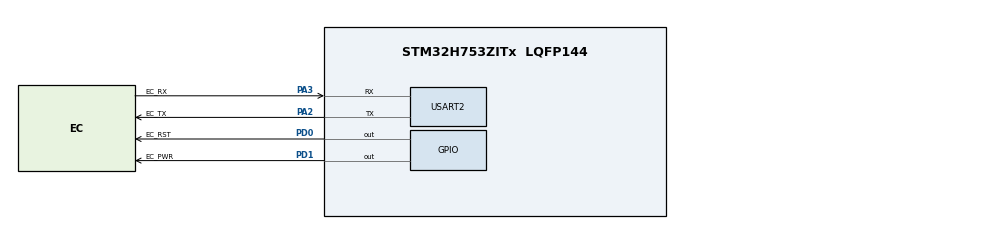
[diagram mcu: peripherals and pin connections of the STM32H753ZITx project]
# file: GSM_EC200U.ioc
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CORTEX_M7.default_mode_Activation=1
Mcu.Family=STM32H7
Mcu.Name=STM32H753ZITx
Mcu.Package=LQFP144
NVIC.PriorityGroup=NVIC_PRIORITYGROUP_4
NVIC.TIM8_TRG_COM_TIM14_IRQn=true\:0\:0\:false\:false\:true\:true\:true\:true
NVIC.USART2_IRQn=true\:0\:0\:false\:false\:true\:true\:true\:true
PA2.GPIO_Label=EC_TX
PA2.Mode=Asynchronous
PA2.Signal=USART2_TX
PA3.GPIO_Label=EC_RX
PA3.Mode=Asynchronous
PA3.Signal=USART2_RX
PD0.GPIO_Label=EC_RST
PD0.GPIO_PuPd=GPIO_PULLDOWN
PD0.Signal=GPIO_Output
PD1.GPIO_Label=EC_PWR
PD1.GPIO_PuPd=GPIO_PULLDOWN
PD1.Signal=GPIO_Output
ProjectManager.HeapSize=0x200
ProjectManager.StackSize=0x400
ProjectManager.TargetToolchain=STM32CubeIDE
RCC.ADCFreq_Value=129000000
RCC.APB1Freq_Value=32000000
RCC.APB2Freq_Value=64000000
RCC.APB3Freq_Value=64000000
RCC.APB4Freq_Value=64000000
RCC.CortexFreq_Value=64000000
RCC.D2PPRE1=RCC_APB1_DIV2
RCC.HCLKFreq_Value=64000000
RCC.SYSCLKFreq_VALUE=64000000
RCC.USBFreq_Value=129000000
TIM14.Period=1000
TIM14.Prescaler=64
USART2.VirtualMode-Asynchronous=VM_ASYNC
VP_MEMORYMAP_VS_MEMORYMAP.Mode=CurAppReg
VP_TIM14_VS_ClockSourceINT.Mode=Enable_Timer
board=custom

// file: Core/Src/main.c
/* USER CODE BEGIN Header */
/**
  ******************************************************************************
  * @file           : main.c
  * @brief          : Main program body
  ******************************************************************************
  * @attention
  *
  * Copyright (c) 2025 STMicroelectronics.
  * All rights reserved.
  *
  * This software is licensed under terms that can be found in the LICENSE file
  * in the root directory of this software component.
  * If no LICENSE file comes with this software, it is provided AS-IS.
  *
  ******************************************************************************
  */
/* USER CODE END Header */

/* USER CODE BEGIN Includes */
#include "Master.h"

/* USER CODE END Includes */

TIM_HandleTypeDef htim14;

UART_HandleTypeDef huart2;

void SystemClock_Config(void);
static void MPU_Config(void);
static void MX_GPIO_Init(void);
static void MX_USART2_UART_Init(void);
static void MX_TIM14_Init(void);

/* USER CODE BEGIN 0 */
char byte = 0;

/* USER CODE END 0 */

int main(void)
{

  /* MPU Configuration--------------------------------------------------------*/
  MPU_Config();

  /* MCU Configuration--------------------------------------------------------*/

  /* Reset of all peripherals, Initializes the Flash interface and the Systick. */
  HAL_Init();

  /* Configure the system clock */
  SystemClock_Config();

  /* Initialize all configured peripherals */
  MX_GPIO_Init();
  MX_USART2_UART_Init();
  MX_TIM14_Init();
  /* USER CODE BEGIN 2 */

//  __RESET_ON__;
//  HAL_Delay(200); // Hold low for at least 150ms
//
//  // Release RESET
//  __RESET_OFF__;
//
//  // Wait for module to boot (around 3 seconds typical)
//  HAL_Delay(5000);

	HAL_UART_Receive_IT(&huart2, &byte, 1);
	HAL_TIM_Base_Start_IT(&htim14);

  /* USER CODE END 2 */

  /* Infinite loop */
  while (1)
  {

  }
}

void SystemClock_Config(void)
{
  RCC_OscInitTypeDef RCC_OscInitStruct = {0};
  RCC_ClkInitTypeDef RCC_ClkInitStruct = {0};

  /** Supply configuration update enable
  */
  HAL_PWREx_ConfigSupply(PWR_LDO_SUPPLY);

  /** Configure the main internal regulator output voltage
  */
  __HAL_PWR_VOLTAGESCALING_CONFIG(PWR_REGULATOR_VOLTAGE_SCALE3);

  while(!__HAL_PWR_GET_FLAG(PWR_FLAG_VOSRDY)) {}

  /** Initializes the RCC Oscillators according to the specified parameters
  * in the RCC_OscInitTypeDef structure.
  */
  RCC_OscInitStruct.OscillatorType = RCC_OSCILLATORTYPE_HSI;
  RCC_OscInitStruct.HSIState = RCC_HSI_DIV1;
  RCC_OscInitStruct.HSICalibrationValue = RCC_HSICALIBRATION_DEFAULT;
  RCC_OscInitStruct.PLL.PLLState = RCC_PLL_NONE;
  if (HAL_RCC_OscConfig(&RCC_OscInitStruct) != HAL_OK)
  {
    Error_Handler();
  }

  /** Initializes the CPU, AHB and APB buses clocks
  */
  RCC_ClkInitStruct.ClockType = RCC_CLOCKTYPE_HCLK|RCC_CLOCKTYPE_SYSCLK
                              |RCC_CLOCKTYPE_PCLK1|RCC_CLOCKTYPE_PCLK2
                              |RCC_CLOCKTYPE_D3PCLK1|RCC_CLOCKTYPE_D1PCLK1;
  RCC_ClkInitStruct.SYSCLKSource = RCC_SYSCLKSOURCE_HSI;
  RCC_ClkInitStruct.SYSCLKDivider = RCC_SYSCLK_DIV1;
  RCC_ClkInitStruct.AHBCLKDivider = RCC_HCLK_DIV1;
  RCC_ClkInitStruct.APB3CLKDivider = RCC_APB3_DIV1;
  RCC_ClkInitStruct.APB1CLKDivider = RCC_APB1_DIV2;
  RCC_ClkInitStruct.APB2CLKDivider = RCC_APB2_DIV1;
  RCC_ClkInitStruct.APB4CLKDivider = RCC_APB4_DIV1;

  if (HAL_RCC_ClockConfig(&RCC_ClkInitStruct, FLASH_LATENCY_1) != HAL_OK)
  {
    Error_Handler();
  }
}

static void MX_TIM14_Init(void)
{

  htim14.Instance = TIM14;
  htim14.Init.Prescaler = 64;
  htim14.Init.CounterMode = TIM_COUNTERMODE_UP;
  htim14.Init.Period = 1000;
  htim14.Init.ClockDivision = TIM_CLOCKDIVISION_DIV1;
  htim14.Init.AutoReloadPreload = TIM_AUTORELOAD_PRELOAD_DISABLE;
  if (HAL_TIM_Base_Init(&htim14) != HAL_OK)
  {
    Error_Handler();
  }

}

static void MX_USART2_UART_Init(void)
{

  huart2.Instance = USART2;
  huart2.Init.BaudRate = 115200;
  huart2.Init.WordLength = UART_WORDLENGTH_8B;
  huart2.Init.StopBits = UART_STOPBITS_1;
  huart2.Init.Parity = UART_PARITY_NONE;
  huart2.Init.Mode = UART_MODE_TX_RX;
  huart2.Init.HwFlowCtl = UART_HWCONTROL_NONE;
  huart2.Init.OverSampling = UART_OVERSAMPLING_16;
  huart2.Init.OneBitSampling = UART_ONE_BIT_SAMPLE_DISABLE;
  huart2.Init.ClockPrescaler = UART_PRESCALER_DIV1;
  huart2.AdvancedInit.AdvFeatureInit = UART_ADVFEATURE_NO_INIT;
  if (HAL_UART_Init(&huart2) != HAL_OK)
  {
    Error_Handler();
  }
  if (HAL_UARTEx_SetTxFifoThreshold(&huart2, UART_TXFIFO_THRESHOLD_1_8) != HAL_OK)
  {
    Error_Handler();
  }
  if (HAL_UARTEx_SetRxFifoThreshold(&huart2, UART_RXFIFO_THRESHOLD_1_8) != HAL_OK)
  {
    Error_Handler();
  }
  if (HAL_UARTEx_DisableFifoMode(&huart2) != HAL_OK)
  {
    Error_Handler();
  }

}

static void MX_GPIO_Init(void)
{
  GPIO_InitTypeDef GPIO_InitStruct = {0};

  /* GPIO Ports Clock Enable */
  __HAL_RCC_GPIOA_CLK_ENABLE();
  __HAL_RCC_GPIOD_CLK_ENABLE();

  /*Configure GPIO pin Output Level */
  HAL_GPIO_WritePin(GPIOD, EC_RST_Pin|EC_PWR_Pin, GPIO_PIN_RESET);

  /*Configure GPIO pins : EC_RST_Pin EC_PWR_Pin */
  GPIO_InitStruct.Pin = EC_RST_Pin|EC_PWR_Pin;
  GPIO_InitStruct.Mode = GPIO_MODE_OUTPUT_PP;
  GPIO_InitStruct.Pull = GPIO_PULLDOWN;
  GPIO_InitStruct.Speed = GPIO_SPEED_FREQ_LOW;
  HAL_GPIO_Init(GPIOD, &GPIO_InitStruct);

}

 /* MPU Configuration */

void MPU_Config(void)
{
  MPU_Region_InitTypeDef MPU_InitStruct = {0};

  /* Disables the MPU */
  HAL_MPU_Disable();

  /** Initializes and configures the Region and the memory to be protected
  */
  MPU_InitStruct.Enable = MPU_REGION_ENABLE;
  MPU_InitStruct.Number = MPU_REGION_NUMBER0;
  MPU_InitStruct.BaseAddress = 0x0;
  MPU_InitStruct.Size = MPU_REGION_SIZE_4GB;
  MPU_InitStruct.SubRegionDisable = 0x87;
  MPU_InitStruct.TypeExtField = MPU_TEX_LEVEL0;
  MPU_InitStruct.AccessPermission = MPU_REGION_NO_ACCESS;
  MPU_InitStruct.DisableExec = MPU_INSTRUCTION_ACCESS_DISABLE;
  MPU_InitStruct.IsShareable = MPU_ACCESS_SHAREABLE;
  MPU_InitStruct.IsCacheable = MPU_ACCESS_NOT_CACHEABLE;
  MPU_InitStruct.IsBufferable = MPU_ACCESS_NOT_BUFFERABLE;

  HAL_MPU_ConfigRegion(&MPU_InitStruct);
  /* Enables the MPU */
  HAL_MPU_Enable(MPU_PRIVILEGED_DEFAULT);

}

void Error_Handler(void)
{
  __disable_irq();
  while (1)
  {
  }
}
